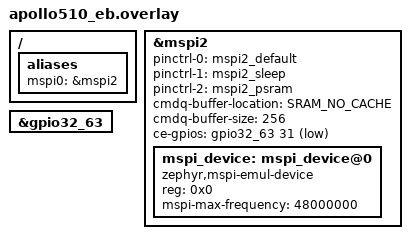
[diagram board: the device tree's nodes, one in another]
/*
 * Copyright (c) 2024 Ambiq Micro Inc. <www.ambiq.com>
 *
 * SPDX-License-Identifier: Apache-2.0
 */
/ {
	aliases {
		mspi0 = &mspi2;
	};
};

&mspi2 {
	pinctrl-0 = <&mspi2_default>;
	pinctrl-1 = <&mspi2_sleep>;
	pinctrl-2 = <&mspi2_psram>;

	cmdq-buffer-location = "SRAM_NO_CACHE";
	cmdq-buffer-size = <256>;

	status = "okay";
	ce-gpios = <&gpio32_63 31 GPIO_ACTIVE_LOW>;

	mspi_device: mspi_device@0 {
		status = "okay";
		compatible = "zephyr,mspi-emul-device";
		reg = <0x0>;
		mspi-max-frequency = <48000000>;
	};
};

&gpio32_63 {
	status = "okay";
};
